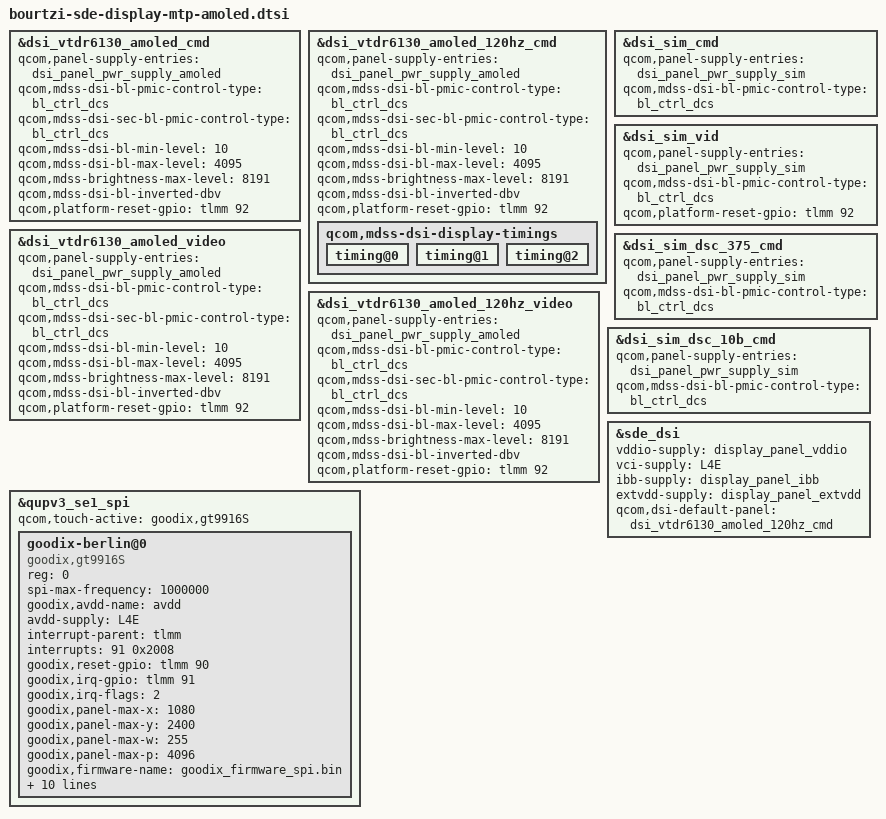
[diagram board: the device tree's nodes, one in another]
// SPDX-License-Identifier: BSD-3-Clause
/*
 * Copyright (c) Qualcomm Technologies, Inc. and/or its subsidiaries.
 */

#include "bourtzi-sde-display.dtsi"

&dsi_vtdr6130_amoled_cmd {
	qcom,panel-supply-entries = <&dsi_panel_pwr_supply_amoled>;
	qcom,mdss-dsi-bl-pmic-control-type = "bl_ctrl_dcs";
	qcom,mdss-dsi-sec-bl-pmic-control-type = "bl_ctrl_dcs";
	qcom,mdss-dsi-bl-min-level = <10>;
	qcom,mdss-dsi-bl-max-level = <4095>;
	qcom,mdss-brightness-max-level = <8191>;
	qcom,mdss-dsi-bl-inverted-dbv;
	qcom,platform-reset-gpio = <&tlmm 92 0>;
};

&dsi_vtdr6130_amoled_120hz_cmd {
	qcom,panel-supply-entries = <&dsi_panel_pwr_supply_amoled>;
	qcom,mdss-dsi-bl-pmic-control-type = "bl_ctrl_dcs";
	qcom,mdss-dsi-sec-bl-pmic-control-type = "bl_ctrl_dcs";
	qcom,mdss-dsi-bl-min-level = <10>;
	qcom,mdss-dsi-bl-max-level = <4095>;
	qcom,mdss-brightness-max-level = <8191>;
	qcom,mdss-dsi-bl-inverted-dbv;
	qcom,platform-reset-gpio = <&tlmm 92 0>;
	qcom,mdss-dsi-display-timings {
		timing@0 {
			/delete-property/ qcom,mdss-dsi-panel-clockrate;
		};
		timing@1 {
			/delete-property/ qcom,mdss-dsi-panel-clockrate;
		};
		timing@2 {
			/delete-property/ qcom,mdss-dsi-panel-clockrate;
		};
	};
};

&dsi_vtdr6130_amoled_video {
	qcom,panel-supply-entries = <&dsi_panel_pwr_supply_amoled>;
	qcom,mdss-dsi-bl-pmic-control-type = "bl_ctrl_dcs";
	qcom,mdss-dsi-sec-bl-pmic-control-type = "bl_ctrl_dcs";
	qcom,mdss-dsi-bl-min-level = <10>;
	qcom,mdss-dsi-bl-max-level = <4095>;
	qcom,mdss-brightness-max-level = <8191>;
	qcom,mdss-dsi-bl-inverted-dbv;
	qcom,platform-reset-gpio = <&tlmm 92 0>;
};

&dsi_vtdr6130_amoled_120hz_video {
	qcom,panel-supply-entries = <&dsi_panel_pwr_supply_amoled>;
	qcom,mdss-dsi-bl-pmic-control-type = "bl_ctrl_dcs";
	qcom,mdss-dsi-sec-bl-pmic-control-type = "bl_ctrl_dcs";
	qcom,mdss-dsi-bl-min-level = <10>;
	qcom,mdss-dsi-bl-max-level = <4095>;
	qcom,mdss-brightness-max-level = <8191>;
	qcom,mdss-dsi-bl-inverted-dbv;
	qcom,platform-reset-gpio = <&tlmm 92 0>;
};

&dsi_sim_cmd {
	qcom,panel-supply-entries = <&dsi_panel_pwr_supply_sim>;
	qcom,mdss-dsi-bl-pmic-control-type = "bl_ctrl_dcs";
};

&dsi_sim_vid {
	qcom,panel-supply-entries = <&dsi_panel_pwr_supply_sim>;
	qcom,mdss-dsi-bl-pmic-control-type = "bl_ctrl_dcs";
	qcom,platform-reset-gpio = <&tlmm 92 0>;
};

&dsi_sim_dsc_375_cmd {
	qcom,panel-supply-entries = <&dsi_panel_pwr_supply_sim>;
	qcom,mdss-dsi-bl-pmic-control-type = "bl_ctrl_dcs";
};

&dsi_sim_dsc_10b_cmd {
	qcom,panel-supply-entries = <&dsi_panel_pwr_supply_sim>;
	qcom,mdss-dsi-bl-pmic-control-type = "bl_ctrl_dcs";
};

&sde_dsi {
	vddio-supply = <&display_panel_vddio>;
	vci-supply = <&L4E>;
	ibb-supply = <&display_panel_ibb>;
	extvdd-supply = <&display_panel_extvdd>;

	qcom,dsi-default-panel = <&dsi_vtdr6130_amoled_120hz_cmd>;
};

&qupv3_se1_spi {
	#address-cells = <1>;
	#size-cells = <0>;
	status = "ok";
	qcom,touch-active = "goodix,gt9916S";

	goodix-berlin@0 {
		compatible = "goodix,gt9916S";
		reg = <0>;
		spi-max-frequency = <1000000>;

		goodix,avdd-name = "avdd";
		avdd-supply = <&L4E>;

		interrupt-parent = <&tlmm>;
		interrupts = <91 0x2008>;
		goodix,reset-gpio = <&tlmm 90 0x00>;
		goodix,irq-gpio = <&tlmm 91 0x2008>;
		goodix,irq-flags = <2>;
		goodix,panel-max-x = <1080>;
		goodix,panel-max-y = <2400>;
		goodix,panel-max-w = <255>;
		goodix,panel-max-p = <4096>;
		goodix,firmware-name = "goodix_firmware_spi.bin";
		goodix,config-name = "goodix_cfg_group_spi.bin";

		pinctrl-names = "pmx_ts_active", "pmx_ts_suspend", "pmx_ts_release";
		pinctrl-0 = <&ts_spi_active>;
		pinctrl-1 = <&ts_spi_int_suspend &ts_spi_reset_suspend>;
		pinctrl-2 = <&ts_spi_release>;

		qcom,touch-environment = "pvm";
		panel = <&dsi_vtdr6130_amoled_cmd
			&dsi_vtdr6130_amoled_120hz_cmd
			&dsi_vtdr6130_amoled_video
			&dsi_vtdr6130_amoled_120hz_video>;
	};
};
